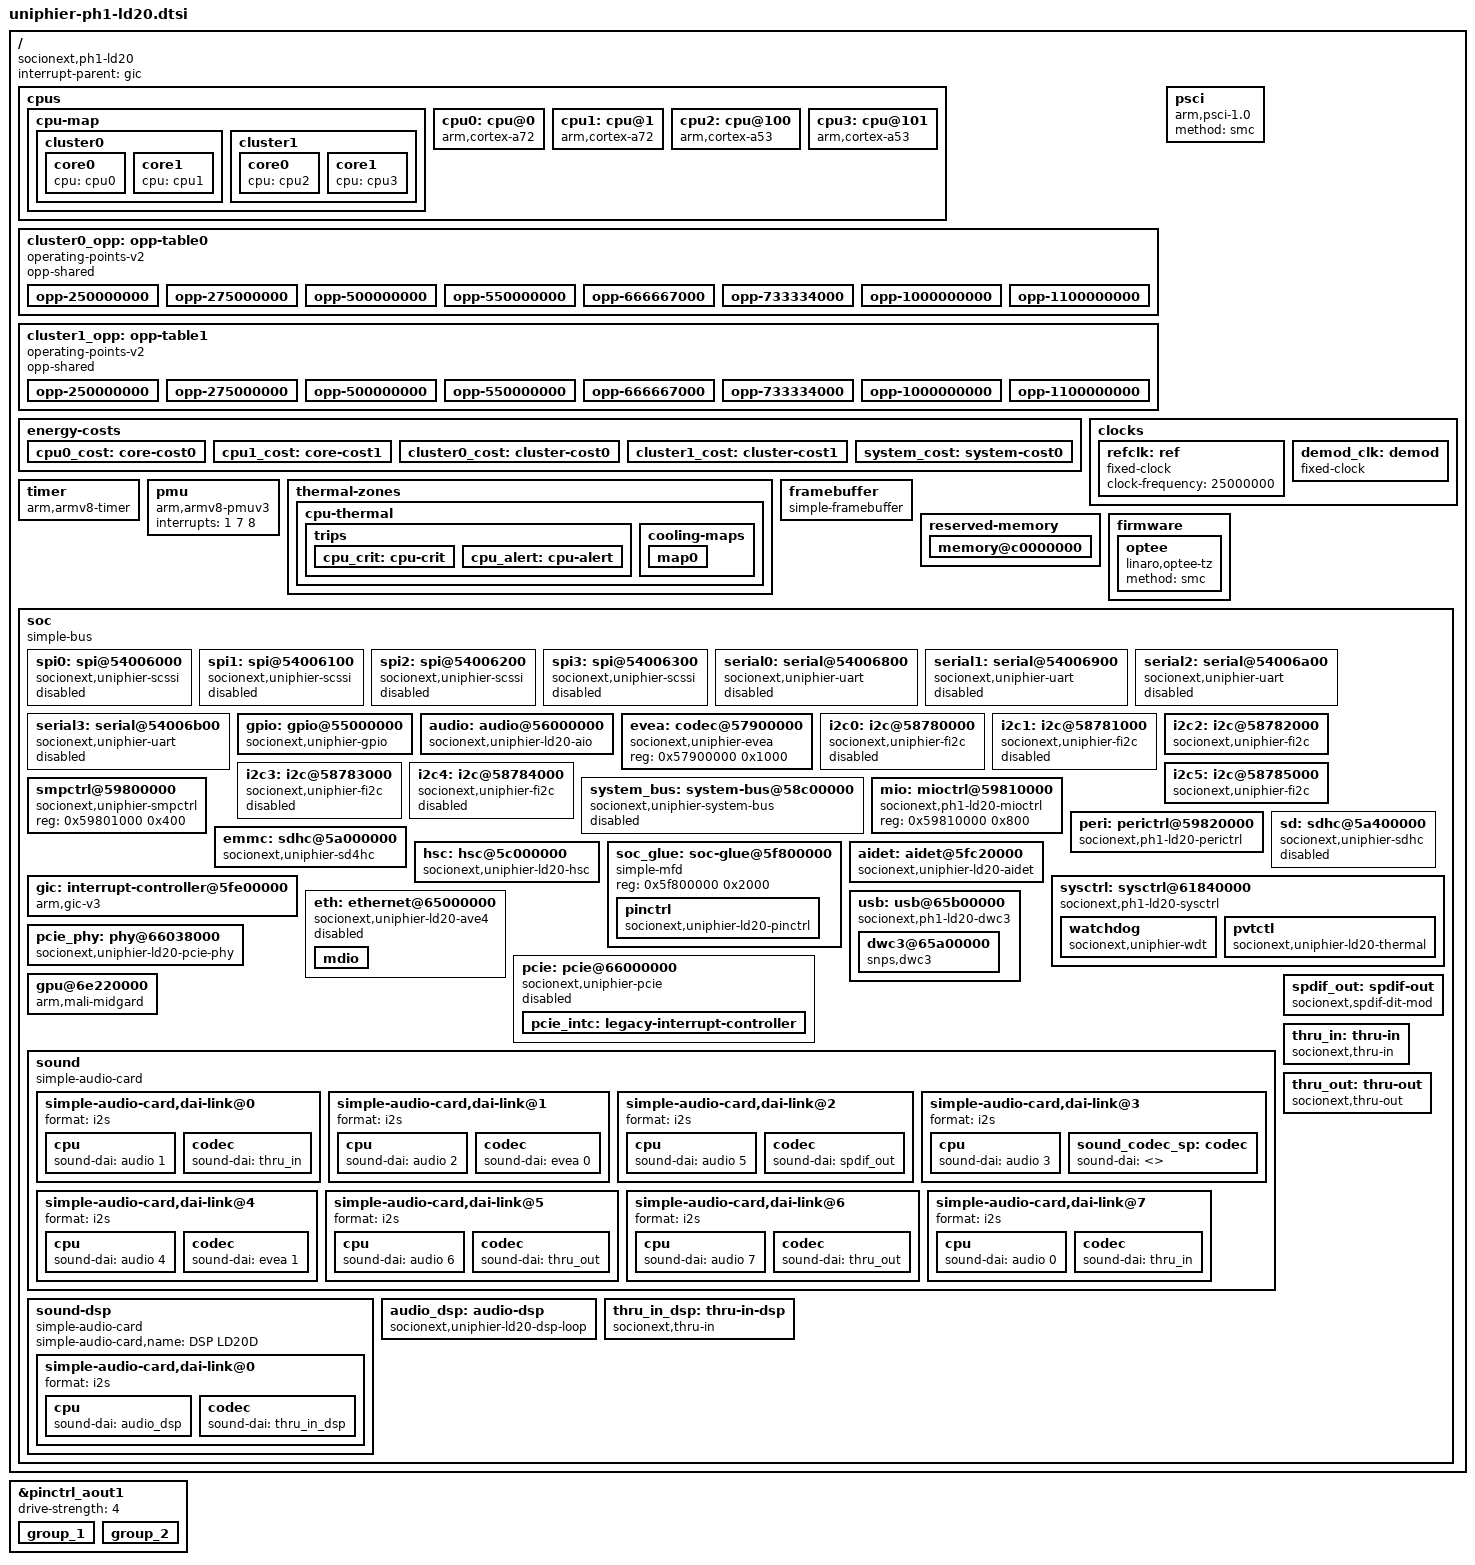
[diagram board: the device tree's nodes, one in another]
// SPDX-Lincense-Identfier: GPL-2.0+ OR MIT
//
// Device Tree Source for UniPhier PH1-LD20 SoC
//
// Copyright (C) 2015 Socionext Inc.
//   Author: Masahiro Yamada <yamada.masahiro@socionext.com>

#include <dt-bindings/gpio/gpio.h>
#include <dt-bindings/gpio/uniphier-gpio.h>
#include <dt-bindings/thermal/thermal.h>

/memreserve/ 0x80000000 0x00080000;

/ {
	compatible = "socionext,ph1-ld20";
	#address-cells = <2>;
	#size-cells = <2>;
	interrupt-parent = <&gic>;

	cpus {
		#address-cells = <2>;
		#size-cells = <0>;

		cpu-map {
			cluster0 {
				core0 {
					cpu = <&cpu0>;
				};
				core1 {
					cpu = <&cpu1>;
				};
			};

			cluster1 {
				core0 {
					cpu = <&cpu2>;
				};
				core1 {
					cpu = <&cpu3>;
				};
			};
		};

		cpu0: cpu@0 {
			device_type = "cpu";
			compatible = "arm,cortex-a72", "arm,armv8";
			reg = <0 0x000>;
			clocks = <&sysctrl 32>;
			enable-method = "psci";
			operating-points-v2 = <&cluster0_opp>;
			#cooling-cells = <2>;
			sched-energy-costs = <&cpu0_cost &cluster0_cost
					      &system_cost>;
		};

		cpu1: cpu@1 {
			device_type = "cpu";
			compatible = "arm,cortex-a72", "arm,armv8";
			reg = <0 0x001>;
			clocks = <&sysctrl 32>;
			enable-method = "psci";
			operating-points-v2 = <&cluster0_opp>;
			#cooling-cells = <2>;
			sched-energy-costs = <&cpu0_cost &cluster0_cost
					      &system_cost>;
		};

		cpu2: cpu@100 {
			device_type = "cpu";
			compatible = "arm,cortex-a53", "arm,armv8";
			reg = <0 0x100>;
			clocks = <&sysctrl 33>;
			enable-method = "psci";
			operating-points-v2 = <&cluster1_opp>;
			#cooling-cells = <2>;
			sched-energy-costs = <&cpu1_cost &cluster1_cost
					      &system_cost>;
		};

		cpu3: cpu@101 {
			device_type = "cpu";
			compatible = "arm,cortex-a53", "arm,armv8";
			reg = <0 0x101>;
			clocks = <&sysctrl 33>;
			enable-method = "psci";
			operating-points-v2 = <&cluster1_opp>;
			#cooling-cells = <2>;
			sched-energy-costs = <&cpu1_cost &cluster1_cost
					      &system_cost>;
		};
	};

	cluster0_opp: opp-table0 {
		compatible = "operating-points-v2";
		opp-shared;

		opp-250000000 {
			opp-hz = /bits/ 64 <250000000>;
			clock-latency-ns = <300>;
		};
		opp-275000000 {
			opp-hz = /bits/ 64 <275000000>;
			clock-latency-ns = <300>;
		};
		opp-500000000 {
			opp-hz = /bits/ 64 <500000000>;
			clock-latency-ns = <300>;
		};
		opp-550000000 {
			opp-hz = /bits/ 64 <550000000>;
			clock-latency-ns = <300>;
		};
		opp-666667000 {
			opp-hz = /bits/ 64 <666667000>;
			clock-latency-ns = <300>;
		};
		opp-733334000 {
			opp-hz = /bits/ 64 <733334000>;
			clock-latency-ns = <300>;
		};
		opp-1000000000 {
			opp-hz = /bits/ 64 <1000000000>;
			clock-latency-ns = <300>;
		};
		opp-1100000000 {
			opp-hz = /bits/ 64 <1100000000>;
			clock-latency-ns = <300>;
		};
	};

	cluster1_opp: opp-table1 {
		compatible = "operating-points-v2";
		opp-shared;

		opp-250000000 {
			opp-hz = /bits/ 64 <250000000>;
			clock-latency-ns = <300>;
		};
		opp-275000000 {
			opp-hz = /bits/ 64 <275000000>;
			clock-latency-ns = <300>;
		};
		opp-500000000 {
			opp-hz = /bits/ 64 <500000000>;
			clock-latency-ns = <300>;
		};
		opp-550000000 {
			opp-hz = /bits/ 64 <550000000>;
			clock-latency-ns = <300>;
		};
		opp-666667000 {
			opp-hz = /bits/ 64 <666667000>;
			clock-latency-ns = <300>;
		};
		opp-733334000 {
			opp-hz = /bits/ 64 <733334000>;
			clock-latency-ns = <300>;
		};
		opp-1000000000 {
			opp-hz = /bits/ 64 <1000000000>;
			clock-latency-ns = <300>;
		};
		opp-1100000000 {
			opp-hz = /bits/ 64 <1100000000>;
			clock-latency-ns = <300>;
		};
	};

	energy-costs {
		cpu0_cost: core-cost0 {
			busy-cost-data = <
				417	168
				579	251
				744	359
				883	479
				1024	616
			>;
			idle-cost-data = <
				15
				0
			>;
		};
		cpu1_cost: core-cost1 {
			busy-cost-data = <
				235	33
				302	46
				368	61
				406	76
				447	93
			>;
			idle-cost-data = <
				6
				0
			>;
		};
		cluster0_cost: cluster-cost0 {
			busy-cost-data = <
				417	22
				579	32
				744	43
				883	53
				1024	64
			>;
			idle-cost-data = <
				65
				24
			>;
		};
		cluster1_cost: cluster-cost1 {
			busy-cost-data = <
				235	22
				303	30
				368	39
				406	47
				447	57
			>;
			idle-cost-data = <
				56
				17
			>;
		};
		system_cost: system-cost0 {
			busy-cost-data = <
				1024	0
			>;
			idle-cost-data = <
				0
				0
			>;
		};
	};

	psci {
		compatible = "arm,psci-1.0";
		method = "smc";
	};

	clocks {
		refclk: ref {
			#clock-cells = <0>;
			compatible = "fixed-clock";
			clock-frequency = <25000000>;
		};

		demod_clk: demod {
			#clock-cells = <0>;
			compatible = "fixed-clock";
			clock-frequency = <25400000>;
			clock-accuracy = <100>;
		};
	};

	timer {
		compatible = "arm,armv8-timer";
		interrupts = <1 13 0xf01>,
			     <1 14 0xf01>,
			     <1 11 0xf01>,
			     <1 10 0xf01>;
	};

	pmu {
		compatible = "arm,armv8-pmuv3";
		interrupts = <1 7 8>;
	};

	thermal-zones {
		cpu-thermal {
			polling-delay-passive = <250>;	/* 250ms */
			polling-delay = <1000>;		/* 1000ms */
			thermal-sensors = <&pvtctl>;

			trips {
				cpu_crit: cpu-crit {
					temperature = <120000>;	/* 120C */
					hysteresis = <2000>;
					type = "critical";
				};
				cpu_alert: cpu-alert {
					temperature = <110000>;	/* 110C */
					hysteresis = <2000>;
					type = "passive";
				};
			};

			cooling-maps {
				map0 {
					trip = <&cpu_alert>;
					cooling-device = <&cpu0 THERMAL_NO_LIMIT THERMAL_NO_LIMIT>,
							 <&cpu1 THERMAL_NO_LIMIT THERMAL_NO_LIMIT>,
							 <&cpu2 THERMAL_NO_LIMIT THERMAL_NO_LIMIT>,
							 <&cpu3 THERMAL_NO_LIMIT THERMAL_NO_LIMIT>;
				};
			};
		};
	};

	framebuffer {
		compatible = "simple-framebuffer";
		reg = <0 0xc0000000 0 0x02000000>;
		width = <3840>;
		height = <2160>;
		stride = <15360>;
		format = "a8r8g8b8";
	};

	reserved-memory {
		#address-cells = <2>;
		#size-cells = <2>;
		ranges;

		memory@c0000000 {
			reg = <0 0xc0000000 0 0x02000000>;
			no-map;
		};
	};

	firmware {
		optee {
			compatible = "linaro,optee-tz";
			method = "smc";
		};
	};

	soc: soc {
		compatible = "simple-bus";
		#address-cells = <1>;
		#size-cells = <1>;
		ranges = <0 0 0 0xffffffff>;

		spi0: spi@54006000 {
			compatible = "socionext,uniphier-scssi";
			status = "disabled";
			reg = <0x54006000 0x100>;
			interrupts = <0 39 4>;
			pinctrl-names = "default";
			pinctrl-0 = <&pinctrl_spi0>;
			clocks = <&peri 11>;
		};

		spi1: spi@54006100 {
			compatible = "socionext,uniphier-scssi";
			status = "disabled";
			reg = <0x54006100 0x100>;
			interrupts = <0 216 4>;
			pinctrl-names = "default";
			pinctrl-0 = <&pinctrl_spi1>;
			clocks = <&peri 11>;
		};

		spi2: spi@54006200 {
			compatible = "socionext,uniphier-scssi";
			status = "disabled";
			reg = <0x54006200 0x100>;
			interrupts = <0 229 4>;
			pinctrl-names = "default";
			pinctrl-0 = <&pinctrl_spi2>;
			clocks = <&peri 11>;
		};

		spi3: spi@54006300 {
			compatible = "socionext,uniphier-scssi";
			status = "disabled";
			reg = <0x54006300 0x100>;
			interrupts = <0 230 4>;
			pinctrl-names = "default";
			pinctrl-0 = <&pinctrl_spi3>;
			clocks = <&peri 11>;
		};

		serial0: serial@54006800 {
			compatible = "socionext,uniphier-uart";
			status = "disabled";
			reg = <0x54006800 0x40>;
			interrupts = <0 33 4>;
			pinctrl-names = "default";
			pinctrl-0 = <&pinctrl_uart0>;
			clocks = <&peri 0>;
		};

		serial1: serial@54006900 {
			compatible = "socionext,uniphier-uart";
			status = "disabled";
			reg = <0x54006900 0x40>;
			interrupts = <0 35 4>;
			pinctrl-names = "default";
			pinctrl-0 = <&pinctrl_uart1>;
			clocks = <&peri 1>;
		};

		serial2: serial@54006a00 {
			compatible = "socionext,uniphier-uart";
			status = "disabled";
			reg = <0x54006a00 0x40>;
			interrupts = <0 37 4>;
			pinctrl-names = "default";
			pinctrl-0 = <&pinctrl_uart2>;
			clocks = <&peri 2>;
		};

		serial3: serial@54006b00 {
			compatible = "socionext,uniphier-uart";
			status = "disabled";
			reg = <0x54006b00 0x40>;
			interrupts = <0 177 4>;
			pinctrl-names = "default";
			pinctrl-0 = <&pinctrl_uart3>;
			clocks = <&peri 3>;
		};

		gpio: gpio@55000000 {
			compatible = "socionext,uniphier-gpio";
			reg = <0x55000000 0x200>;
			interrupt-parent = <&aidet>;
			interrupt-controller;
			#interrupt-cells = <2>;
			gpio-controller;
			#gpio-cells = <2>;
			gpio-ranges = <&pinctrl 0 0 0>,
				      <&pinctrl 96 0 0>,
				      <&pinctrl 160 0 0>;
			gpio-ranges-group-names = "gpio_range0",
						  "gpio_range1",
						  "gpio_range2";
			ngpios = <205>;
			socionext,interrupt-ranges = <0 48 16>, <16 154 5>,
						     <21 217 3>;
		};

		audio: audio@56000000 {
			compatible = "socionext,uniphier-ld20-aio";
			reg = <0x56000000 0x80000>;
			interrupts = <0 144 4>;
			pinctrl-names = "default";
			pinctrl-0 = <&pinctrl_aout1>;
			#sound-dai-cells = <1>;
			socionext,syscon = <&soc_glue>;
		};

		evea: codec@57900000 {
			compatible = "socionext,uniphier-evea";
			reg = <0x57900000 0x1000>;
			#sound-dai-cells = <1>;
		};

		i2c0: i2c@58780000 {
			compatible = "socionext,uniphier-fi2c";
			status = "disabled";
			reg = <0x58780000 0x80>;
			#address-cells = <1>;
			#size-cells = <0>;
			interrupts = <0 41 4>;
			pinctrl-names = "default";
			pinctrl-0 = <&pinctrl_i2c0>;
			clocks = <&peri 4>;
			clock-frequency = <100000>;
		};

		i2c1: i2c@58781000 {
			compatible = "socionext,uniphier-fi2c";
			status = "disabled";
			reg = <0x58781000 0x80>;
			#address-cells = <1>;
			#size-cells = <0>;
			interrupts = <0 42 4>;
			pinctrl-names = "default";
			pinctrl-0 = <&pinctrl_i2c1>;
			clocks = <&peri 5>;
			clock-frequency = <100000>;
		};

		i2c2: i2c@58782000 {
			compatible = "socionext,uniphier-fi2c";
			reg = <0x58782000 0x80>;
			#address-cells = <1>;
			#size-cells = <0>;
			interrupts = <0 43 4>;
			clocks = <&peri 6>;
			clock-frequency = <100000>;
		};

		i2c3: i2c@58783000 {
			compatible = "socionext,uniphier-fi2c";
			status = "disabled";
			reg = <0x58783000 0x80>;
			#address-cells = <1>;
			#size-cells = <0>;
			interrupts = <0 44 4>;
			pinctrl-names = "default";
			pinctrl-0 = <&pinctrl_i2c3>;
			clocks = <&peri 7>;
			clock-frequency = <100000>;
		};

		i2c4: i2c@58784000 {
			compatible = "socionext,uniphier-fi2c";
			status = "disabled";
			reg = <0x58784000 0x80>;
			#address-cells = <1>;
			#size-cells = <0>;
			interrupts = <0 45 4>;
			pinctrl-names = "default";
			pinctrl-0 = <&pinctrl_i2c4>;
			clocks = <&peri 8>;
			clock-frequency = <100000>;
		};

		i2c5: i2c@58785000 {
			compatible = "socionext,uniphier-fi2c";
			reg = <0x58785000 0x80>;
			#address-cells = <1>;
			#size-cells = <0>;
			interrupts = <0 25 4>;
			clocks = <&peri 9>;
			clock-frequency = <400000>;
		};

		system_bus: system-bus@58c00000 {
			compatible = "socionext,uniphier-system-bus";
			status = "disabled";
			reg = <0x58c00000 0x400>;
			#address-cells = <2>;
			#size-cells = <1>;
			pinctrl-names = "default";
			pinctrl-0 = <&pinctrl_system_bus>;
		};

		smpctrl@59800000 {
			compatible = "socionext,uniphier-smpctrl";
			reg = <0x59801000 0x400>;
		};

		mio: mioctrl@59810000 {
			compatible = "socionext,ph1-ld20-mioctrl";
			reg = <0x59810000 0x800>;
			#clock-cells = <1>;
		};

		peri: perictrl@59820000 {
			compatible = "socionext,ph1-ld20-perictrl";
			reg = <0x59820000 0x200>;
			#clock-cells = <1>;
			clock-names = "uart", "fi2c", "spi";
			clocks = <&sysctrl 3>, <&sysctrl 4>, <&sysctrl 5>;
		};

		emmc: sdhc@5a000000 {
			compatible = "socionext,uniphier-sd4hc", "cdns,sd4hc";
			reg = <0x5a000000 0x400>;
			interrupts = <0 78 4>;
			pinctrl-names = "default";
			pinctrl-0 = <&pinctrl_emmc_1v8>;
			clocks = <&refclk>; /* fake */
			bus-width = <8>;
			mmc-hs200-1_8v;
			cdns,phy-input-delay-legacy = <9>;
			cdns,phy-input-delay-mmc-highspeed = <2>;
			cdns,phy-input-delay-mmc-ddr = <3>;
			cdns,phy-dll-delay-sdclk = <21>;
			cdns,phy-dll-delay-sdclk-hsmmc = <21>;
		};

		sd: sdhc@5a400000 {
			compatible = "socionext,uniphier-sdhc";
			status = "disabled";
			reg = <0x5a400000 0x800>;
			interrupts = <0 76 4>;
			pinctrl-names = "default";
			pinctrl-0 = <&pinctrl_sd>;
			clock-names = "host";
			clocks = <&mio 0>;
			bus-width = <4>;
			cap-sd-highspeed;
		};

		hsc: hsc@5c000000 {
			compatible = "socionext,uniphier-ld20-hsc";
			reg = <0x5c000000 0x100000>;
			interrupts = <0 100 4>, <0 101 4>;
			pinctrl-names = "default";
			pinctrl-0 = <&pinctrl_hscin2_s>, <&pinctrl_hscin3_s>,
				    <&pinctrl_hscin4_s>;
			clock-names = "stdmac";
			clocks = <&sysctrl 10>;
		};

		soc_glue: soc-glue@5f800000 {
			compatible = "simple-mfd", "syscon";
			reg = <0x5f800000 0x2000>;

			pinctrl: pinctrl {
				 compatible = "socionext,uniphier-ld20-pinctrl";
			};
		};

		aidet: aidet@5fc20000 {
			compatible = "socionext,uniphier-ld20-aidet";
			reg = <0x5fc20000 0x200>;
			interrupt-controller;
			#interrupt-cells = <2>;
		};

		gic: interrupt-controller@5fe00000 {
			compatible = "arm,gic-v3";
			reg = <0x5fe00000 0x10000>,	/* GICD */
			      <0x5fe80000 0x80000>;	/* GICR */
			interrupt-controller;
			#interrupt-cells = <3>;
			interrupts = <1 9 4>;
		};

		sysctrl: sysctrl@61840000 {
			compatible = "socionext,ph1-ld20-sysctrl",
				     "simple-mfd", "syscon";
			reg = <0x61840000 0x10000>;
			#clock-cells = <1>;
			clock-names = "ref";
			clocks = <&refclk>;

			watchdog {
				compatible = "socionext,uniphier-wdt";
			};

			pvtctl: pvtctl {
				compatible = "socionext,uniphier-ld20-thermal";
				interrupts = <0 3 4>;
				#thermal-sensor-cells = <0>;
				socionext,tmod-calibration = <0x0f22 0x68ee>;
			};
		};

		eth: ethernet@65000000 {
			compatible = "socionext,uniphier-ld20-ave4";
			status = "disabled";
			reg = <0x65000000 0x8500>;
			interrupts = <0 66 4>;
			pinctrl-names = "default";
			pinctrl-0 = <&pinctrl_ether_rgmii>;
			clock-names = "ether";
			clocks = <&sysctrl 8>;
			phy-mode = "rgmii";
			local-mac-address = [00 00 00 00 00 00];
			socionext,syscon-phy-mode = <&soc_glue 0>;

			mdio: mdio {
				#address-cells = <1>;
				#size-cells = <0>;
			};
		};

		usb: usb@65b00000 {
			compatible = "socionext,ph1-ld20-dwc3";
			pinctrl-names = "default";
			pinctrl-0 = <&pinctrl_usb0>, <&pinctrl_usb1>, <&pinctrl_usb2>, <&pinctrl_usb3>;
			reg = <0x65b00000 0x1000>;
			clocks = <&sysctrl 20>,<&sysctrl 21>,<&sysctrl 22>,<&sysctrl 23>;
			clock-names = "u3clk0", "u3clk1", "u2clk0", "u2clk1";
			#address-cells = <1>;
			#size-cells = <1>;
			ranges;
			dwc3@65a00000 {
				compatible = "snps,dwc3";
				reg = <0x65a00000 0xcd00>;
				interrupts = <0 134 4>;
				dr_mode = "host";
				tx-fifo-resize;
				snps,dis_u3_susply_quirk;
			};
		};

		pcie: pcie@66000000 {
			compatible = "socionext,uniphier-pcie", "snps,dw-pcie";
			status = "disabled";
			reg-names = "dbi", "link", "config";
			reg = <0x66000000 0x1000>, <0x66010000 0x10000>,
			      <0x2fff0000 0x10000>;
			#address-cells = <3>;
			#size-cells = <2>;
			clocks = <&sysctrl 27>;
			num-lanes = <1>;
			num-viewport = <1>;
			bus-range = <0x0 0xff>;
			device_type = "pci";
			ranges =
			/* downstream I/O */
				<0x81000000 0 0x00000000  0x2ffe0000  0 0x00010000
			/* non-prefetchable memory */
				 0x82000000 0 0x20000000  0x20000000  0 0x0ffe0000>;
			#interrupt-cells = <1>;
			interrupt-names = "dma", "msi";
			interrupts = <0 224 4>, <0 225 4>;
			interrupt-map-mask = <0 0 0  7>;
			interrupt-map = <0 0 0  1  &pcie_intc 0>,	/* INTA */
					<0 0 0  2  &pcie_intc 1>,	/* INTB */
					<0 0 0  3  &pcie_intc 2>,	/* INTC */
					<0 0 0  4  &pcie_intc 3>;	/* INTD */
			phy-names = "pcie-phy";
			phys = <&pcie_phy>;

			pcie_intc: legacy-interrupt-controller {
				interrupt-controller;
				#interrupt-cells = <1>;
				interrupt-parent = <&gic>;
				interrupts = <0 226 4>;
			};
		};

		pcie_phy: phy@66038000 {
			compatible = "socionext,uniphier-ld20-pcie-phy";
			reg = <0x66038000 0x4000>;
			#phy-cells = <0>;
			clocks = <&sysctrl 27>;
			socionext,syscon = <&soc_glue>;
		};

		gpu@6e220000 {
			compatible = "arm,mali-midgard";
			reg = <0x6e220000 0x4000>;
			interrupt-names = "JOB", "MMU", "GPU";
			interrupts = <0 239 0>, /* JOB */
				     <0 240 0>, /* MMU */
				     <0 238 0>; /* GPU */
			clock-names = "clk_mali";
			clocks = <&refclk>; /* fake */
		};

		sound {
			compatible = "simple-audio-card";
			simple-audio-card,name = "UniPhier LD20";
			simple-audio-card,widgets = "Headphone", "Headphone Jack";

			simple-audio-card,dai-link@0 {
				/* SIF in 1 */
				format = "i2s";
				cpu {
					sound-dai = <&audio 1>;
				};
				codec {
					sound-dai = <&thru_in>;
				};
			};
			simple-audio-card,dai-link@1 {
				/* Line in/out 1 */
				format = "i2s";
				cpu {
					sound-dai = <&audio 2>;
				};
				codec {
					sound-dai = <&evea 0>;
				};
			};
			simple-audio-card,dai-link@2 {
				/* SPDIF */
				format = "i2s";
				cpu {
					sound-dai = <&audio 5>;
				};
				codec {
					sound-dai = <&spdif_out>;
				};
			};
			simple-audio-card,dai-link@3 {
				/* Speaker */
				format = "i2s";
				cpu {
					sound-dai = <&audio 3>;
				};
				sound_codec_sp: codec {
					/* external codec */
					sound-dai = <>;
				};
			};
			simple-audio-card,dai-link@4 {
				/* Headphone */
				format = "i2s";
				cpu {
					sound-dai = <&audio 4>;
				};
				codec {
					sound-dai = <&evea 1>;
				};
			};
			simple-audio-card,dai-link@5 {
				/* SRC0 */
				format = "i2s";
				cpu {
					sound-dai = <&audio 6>;
				};
				codec {
					sound-dai = <&thru_out>;
				};
			};
			simple-audio-card,dai-link@6 {
				/* SRC1 */
				format = "i2s";
				cpu {
					sound-dai = <&audio 7>;
				};
				codec {
					sound-dai = <&thru_out>;
				};
			};
			simple-audio-card,dai-link@7 {
				/* HDMI in/out */
				format = "i2s";
				cpu {
					sound-dai = <&audio 0>;
				};
				codec {
					sound-dai = <&thru_in>;
				};
			};
		};

		sound-dsp {
			compatible = "simple-audio-card";
			simple-audio-card,name = "DSP LD20D";

			simple-audio-card,dai-link@0 {
				/* BT in */
				format = "i2s";
				cpu {
					sound-dai = <&audio_dsp>;
				};
				codec {
					sound-dai = <&thru_in_dsp>;
				};
			};
		};

		spdif_out: spdif-out {
			compatible = "socionext,spdif-dit-mod";
			#sound-dai-cells = <0>;
		};

		thru_in: thru-in {
			compatible = "socionext,thru-in";
			#sound-dai-cells = <0>;
		};

		thru_out: thru-out {
			compatible = "socionext,thru-out";
			#sound-dai-cells = <0>;
		};

		audio_dsp: audio-dsp {
			compatible = "socionext,uniphier-ld20-dsp-loop";
			#sound-dai-cells = <0>;
		};

		thru_in_dsp: thru-in-dsp {
			compatible = "socionext,thru-in";
			#sound-dai-cells = <0>;
		};
	};
};

#include "uniphier-pinctrl.dtsi"

&pinctrl_aout1 {
	drive-strength = <4>;	/* default: 3.5mA */
	group_1 {
		pins = "AO1DACCK";
		drive-strength = <5>;	/* 5mA */
	};
	group_2 {
		pins = "AO1ARC";
		drive-strength = <11>;	/* 11mA */
	};
};
